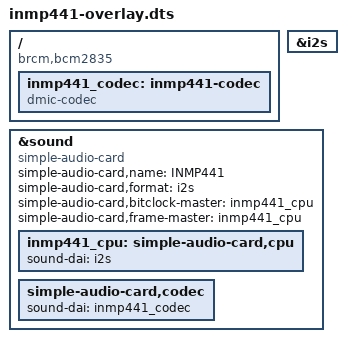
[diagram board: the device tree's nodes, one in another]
// INMP441 digital I2S microphone for Raspberry Pi Zero.
/dts-v1/;
/plugin/;
/ {
     compatible = "brcm,bcm2835";

     fragment@0 {
         target = <&i2s>;
         __overlay__ {
             status = "okay";
         };
     };

     fragment@1 {
         target-path = "/";
         __overlay__ {
             inmp441_codec: inmp441-codec {
                 #sound-dai-cells = <0>;
                 compatible = "dmic-codec";
                 status = "okay";
             };
         };
     };

     fragment@2 {
         target = <&sound>;
         __overlay__ {
             compatible = "simple-audio-card";
             simple-audio-card,name = "INMP441";
             simple-audio-card,format = "i2s";
             simple-audio-card,bitclock-master = <&inmp441_cpu>;
             simple-audio-card,frame-master = <&inmp441_cpu>;
             status = "okay";

             inmp441_cpu: simple-audio-card,cpu {
                 sound-dai = <&i2s>;
             };

             simple-audio-card,codec {
                 sound-dai = <&inmp441_codec>;
             };
         };
     };
 };
